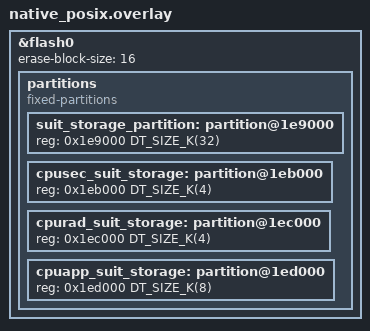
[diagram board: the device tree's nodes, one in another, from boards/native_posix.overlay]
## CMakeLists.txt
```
#
# Copyright (c) 2024 Nordic Semiconductor ASA
#
# SPDX-License-Identifier: LicenseRef-Nordic-5-Clause
#

cmake_minimum_required(VERSION 3.20.0)

find_package(Zephyr REQUIRED HINTS $ENV{ZEPHYR_BASE})

project(integration_suit_component_compatibility_check)
include(../cmake/test_template.cmake)

target_include_directories(app PRIVATE
  ${SUIT_SUBSYS_DIR}/mci/include
  ${SUIT_SUBSYS_DIR}/storage/include
)

target_sources(app PRIVATE
  # Use nRF54H20-specific MCI implementation.
  ${SUIT_SUBSYS_DIR}/mci/src/suit_mci_nrf54h20.c
  ${SUIT_SUBSYS_DIR}/platform/sdfw/src/suit_plat_component_compatibility.c
  ${SUIT_SUBSYS_DIR}/storage/src/suit_storage_nrf54h20.c
)

# Link with the CMake target, that includes SUIT platform internal APIs header
zephyr_library_link_libraries(suit_utils)
zephyr_library_link_libraries(suit_storage_interface)
zephyr_library_link_libraries(suit_platform_interface)
```

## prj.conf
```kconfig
#
# Copyright (c) 2024 Nordic Semiconductor ASA
#
# SPDX-License-Identifier: LicenseRef-Nordic-5-Clause
#

CONFIG_ZTEST=y

CONFIG_SUIT=y
CONFIG_SUIT_PROCESSOR=y
CONFIG_SUIT_UTILS=y
CONFIG_SUIT_MEMPTR_STORAGE=y

# Enable component-compatibility checks
CONFIG_SUIT_PLATFORM=y
CONFIG_SUIT_PLATFORM_VARIANT_SDFW=y

CONFIG_SUIT_STORAGE=y
CONFIG_SUIT_METADATA=y
# nRF54H20 storage uses SHA-256 to protect MPI and NVVs:
CONFIG_SUIT_CRYPTO=y
CONFIG_SUIT_EXECUTION_MODE=y

CONFIG_ZCBOR=y
CONFIG_ZCBOR_CANONICAL=y

CONFIG_FLASH=y

# Mock SDFW arbiter
CONFIG_MOCK_SDFW_ARBITER=y
```

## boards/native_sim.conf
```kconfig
#
# Copyright (c) 2024 Nordic Semiconductor ASA
#
# SPDX-License-Identifier: LicenseRef-Nordic-5-Clause
#

CONFIG_FLASH_SIMULATOR=y
# Mock processor IDs, defined in nrfx
CONFIG_MOCK_NRFX=y
```

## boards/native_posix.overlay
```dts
/*
 * Copyright (c) 2024 Nordic Semiconductor ASA
 *
 * SPDX-License-Identifier: LicenseRef-Nordic-5-Clause
 */

&flash0 {
	/* Align erase block size with the nRF54H20 MRAM definition. */
	erase-block-size = <16>;

	partitions {
		compatible = "fixed-partitions";
		#address-cells = <1>;
		#size-cells = <1>;

		/* Use the last 32 kB of SecDom SUIT NVM storage. */
		suit_storage_partition: partition@1e9000 {
			reg = <0x1e9000 DT_SIZE_K(32)>;
		};

		/* Use the first 4kB as area reserved for Secure domain. */
		cpusec_suit_storage: partition@1eb000 {
			reg = <0x1eb000 DT_SIZE_K(4)>;
		};

		/* Use the next 4kB as area reserved for Radio domain. */
		cpurad_suit_storage: partition@1ec000 {
			reg = <0x1ec000 DT_SIZE_K(4)>;
		};

		/* Use the next 8kB as area reserved for Application domain. */
		cpuapp_suit_storage: partition@1ed000 {
			reg = <0x1ed000 DT_SIZE_K(8)>;
		};
	};
};
```

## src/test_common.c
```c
/*
 * Copyright (c) 2024 Nordic Semiconductor ASA
 *
 * SPDX-License-Identifier: LicenseRef-Nordic-5-Clause
 */

#include <zephyr/ztest.h>
#include <suit_storage_mpi.h>
#include <suit_plat_mem_util.h>
#include "test_common.h"

#define SUIT_STORAGE_NORDIC_OFFSET FIXED_PARTITION_OFFSET(cpusec_suit_storage)
#define SUIT_STORAGE_NORDIC_SIZE   FIXED_PARTITION_SIZE(cpusec_suit_storage)
#define SUIT_STORAGE_RAD_OFFSET	   FIXED_PARTITION_OFFSET(cpurad_suit_storage)
#define SUIT_STORAGE_RAD_SIZE	   FIXED_PARTITION_SIZE(cpurad_suit_storage)
#define SUIT_STORAGE_APP_OFFSET	   FIXED_PARTITION_OFFSET(cpuapp_suit_storage)
#define SUIT_STORAGE_APP_SIZE	   FIXED_PARTITION_SIZE(cpuapp_suit_storage)

#define SUIT_STORAGE_APP_MPI_SIZE 0xf0
#define SUIT_STORAGE_RAD_MPI_SIZE 0x90

/* clang-format off */

/* RFC4122 uuid5(uuid.NAMESPACE_DNS, 'nordicsemi.com') */
const suit_manifest_class_id_t nordic_vid = {{
	0x76, 0x17, 0xda, 0xa5, 0x71, 0xfd, 0x5a, 0x85,
	0x8f, 0x94, 0xe2, 0x8d, 0x73, 0x5c, 0xe9, 0xf4
}};

/* RFC4122 uuid5(nordic_vid, 'nRF54H20_nordic_top') */
const suit_manifest_class_id_t nordic_top_cid = {{
	0xf0, 0x3d, 0x38, 0x5e, 0xa7, 0x31, 0x56, 0x05,
	0xb1, 0x5d, 0x03, 0x7f, 0x6d, 0xa6, 0x09, 0x7f
}};

/* RFC4122 uuid5(nordic_vid, 'nRF54H20_sec') */
const suit_manifest_class_id_t nordic_sdfw_cid = {{
	0xd9, 0x6b, 0x40, 0xb7, 0x09, 0x2b, 0x5c, 0xd1,
	0xa5, 0x9f, 0x9a, 0xf8, 0x0c, 0x33, 0x7e, 0xba
}};

/* RFC4122 uuid5(nordic_vid, 'nRF54H20_sys') */
const suit_manifest_class_id_t nordic_scfw_cid = {{
	0xc0, 0x8a, 0x25, 0xd7, 0x35, 0xe6, 0x59, 0x2c,
	0xb7, 0xad, 0x43, 0xac, 0xc8, 0xd1, 0xd1, 0xc8
}};

/* RFC4122 uuid5(nordic_vid, 'test_sample_root') */
const suit_manifest_class_id_t app_root_cid = {{
	0x97, 0x05, 0x48, 0x23, 0x4c, 0x3d, 0x59, 0xa1,
	0x89, 0x86, 0xa5, 0x46, 0x60, 0xa1, 0x4b, 0x0a,
}};

/* RFC4122 uuid5(nordic_vid, 'test_sample_app') */
const suit_manifest_class_id_t app_local_cid = {{
	0x5b, 0x46, 0x9f, 0xd1, 0x90, 0xee, 0x53, 0x9c,
	0xa3, 0x18, 0x68, 0x1b, 0x03, 0x69, 0x5e, 0x36,
}};

/* clang-format on */

void erase_area_nordic(void)
{
	/* Clear the whole nordic area */
	const struct device *fdev = SUIT_PLAT_INTERNAL_NVM_DEV;

	zassert_not_null(fdev, "Unable to find a driver to modify MPI area");

	int err = flash_erase(fdev, SUIT_STORAGE_NORDIC_OFFSET, SUIT_STORAGE_NORDIC_SIZE);

	zassert_equal(0, err, "Unable to erase nordic area before test execution");
}

void erase_area_rad(void)
{
	/* Clear the whole radio area */
	const struct device *fdev = SUIT_PLAT_INTERNAL_NVM_DEV;

	zassert_not_null(fdev, "Unable to find a driver to modify MPI area");

	int err = flash_erase(fdev, SUIT_STORAGE_RAD_OFFSET, SUIT_STORAGE_RAD_SIZE);

	zassert_equal(0, err, "Unable to erase radio core area before test execution");
}

void erase_area_app(void)
{
	/* Clear the whole application area */
	const struct device *fdev = SUIT_PLAT_INTERNAL_NVM_DEV;

	zassert_not_null(fdev, "Unable to find a driver to modify MPI area");

	int err = flash_erase(fdev, SUIT_STORAGE_APP_OFFSET, SUIT_STORAGE_APP_SIZE);

	zassert_equal(0, err, "Unable to erase application area before test execution");
}

void write_area_app(void)
{
	/* clang-format off */
	uint8_t mpi_root[] = {
		/* Application root MPI area */
		0x01, /* version */
		0x01, /* downgrade prevention disabled */
		0x02, /* Independent update allowed */
		0x01, /* signature check disabled */
		/* reserved (12) */
		0xFF, 0xFF, 0xFF, 0xFF,
		0xFF, 0xFF, 0xFF, 0xFF, 0xFF, 0xFF, 0xFF, 0xFF,
		/* RFC4122 uuid5(uuid.NAMESPACE_DNS, 'nordicsemi.com') */
		0x76, 0x17, 0xda, 0xa5, 0x71, 0xfd, 0x5a, 0x85,
		0x8f, 0x94, 0xe2, 0x8d, 0x73, 0x5c, 0xe9, 0xf4,
		/* RFC4122 uuid5(nordic_vid, 'test_sample_root') */
		0x97, 0x05, 0x48, 0x23, 0x4c, 0x3d, 0x59, 0xa1,
		0x89, 0x86, 0xa5, 0x46, 0x60, 0xa1, 0x4b, 0x0a,
		/* Application recovery MPI area (48) */
		0xFF, 0xFF, 0xFF, 0xFF, 0xFF, 0xFF, 0xFF, 0xFF,
		0xFF, 0xFF, 0xFF, 0xFF, 0xFF, 0xFF, 0xFF, 0xFF,
		0xFF, 0xFF, 0xFF, 0xFF, 0xFF, 0xFF, 0xFF, 0xFF,
		0xFF, 0xFF, 0xFF, 0xFF, 0xFF, 0xFF, 0xFF, 0xFF,
		0xFF, 0xFF, 0xFF, 0xFF, 0xFF, 0xFF, 0xFF, 0xFF,
		0xFF, 0xFF, 0xFF, 0xFF, 0xFF, 0xFF, 0xFF, 0xFF,
		/* Application local 1 MPI area */
		0x01, /* version */
		0x01, /* downgrade prevention disabled */
		0x01, /* Independent update denied */
		0x01, /* signature check disabled */
		/* reserved (12) */
		0xFF, 0xFF, 0xFF, 0xFF,
		0xFF, 0xFF, 0xFF, 0xFF, 0xFF, 0xFF, 0xFF, 0xFF,
		/* RFC4122 uuid5(uuid.NAMESPACE_DNS, 'nordicsemi.com') */
		0x76, 0x17, 0xda, 0xa5, 0x71, 0xfd, 0x5a, 0x85,
		0x8f, 0x94, 0xe2, 0x8d, 0x73, 0x5c, 0xe9, 0xf4,
		/* RFC4122 uuid5(nordic_vid, 'test_sample_app') */
		0x5b, 0x46, 0x9f, 0xd1, 0x90, 0xee, 0x53, 0x9c,
		0xa3, 0x18, 0x68, 0x1b, 0x03, 0x69, 0x5e, 0x36,
	};
	uint8_t app_digest[] = {
		0x44, 0xdc, 0x3d, 0xc5, 0xf3, 0xab, 0x75, 0xa5,
		0x22, 0xd6, 0x42, 0xce, 0x92, 0xb8, 0xbe, 0xf4,
		0x60, 0xcd, 0x7c, 0xab, 0xfa, 0x18, 0x8b, 0x91,
		0x69, 0x32, 0x0a, 0x8b, 0x9e, 0x35, 0x28, 0xa9,
	};
	/* clang-format on */

	/* Write the sample application area (just the root MPI) and corresponding digest */
	const struct device *fdev = SUIT_PLAT_INTERNAL_NVM_DEV;

	zassert_not_null(fdev, "Unable to find a driver to modify MPI area");

	int err = flash_write(fdev, SUIT_STORAGE_APP_OFFSET, mpi_root, sizeof(mpi_root));

	zassert_equal(0, err,
		      "Unable to store application root MPI contents before test execution");

	err = flash_write(fdev, SUIT_STORAGE_APP_OFFSET + SUIT_STORAGE_APP_MPI_SIZE, app_digest,
			  sizeof(app_digest));
	zassert_equal(0, err, "Unable to store application MPI digest before test execution");
}

void assert_nordic_classes(void)
{
	suit_manifest_class_info_t class_infos[CONFIG_SUIT_STORAGE_N_ENVELOPES];
	size_t class_infos_len = CONFIG_SUIT_STORAGE_N_ENVELOPES;

	/* ASSERT that it is possible to fetch list of supported manifest classes and roles */
	int err = suit_storage_mpi_class_ids_get(class_infos, &class_infos_len);

	zassert_equal(err, SUIT_PLAT_SUCCESS,
		      "Failed to fetch list of supported manifest classes (%d).", err);
	/* ... and MPI reports at least 3 class IDs */
	zassert_true(class_infos_len >= 3,
		     "Invalid number of supported manifest classes (%d < %d).", class_infos_len, 3);
	/* ... and the Nordic top manifest class is supported */
	zassert_mem_equal(class_infos[0].vendor_id, &nordic_vid, sizeof(nordic_vid));
	zassert_mem_equal(class_infos[0].class_id, &nordic_top_cid, sizeof(nordic_top_cid));
	zassert_equal(class_infos[0].role, SUIT_MANIFEST_SEC_TOP, "Invalid class role returned: %d",
		      class_infos[0].role);
	/* ... and the Nordic secure domain update & recovery manifest class is supported */
	zassert_mem_equal(class_infos[1].vendor_id, &nordic_vid, sizeof(nordic_vid));
	zassert_mem_equal(class_infos[1].class_id, &nordic_sdfw_cid, sizeof(nordic_sdfw_cid));
	zassert_equal(class_infos[1].role, SUIT_MANIFEST_SEC_SDFW,
		      "Invalid class role returned: %d", class_infos[3].role);
	/* ... and the Nordic system controller manifest class is supported */
	zassert_mem_equal(class_infos[2].vendor_id, &nordic_vid, sizeof(nordic_vid));
	zassert_mem_equal(class_infos[2].class_id, &nordic_scfw_cid, sizeof(nordic_scfw_cid));
	zassert_equal(class_infos[2].role, SUIT_MANIFEST_SEC_SYSCTRL,
		      "Invalid class role returned: %d", class_infos[3].role);
}

void assert_sample_app_classes(void)
{
	suit_manifest_class_info_t class_infos[CONFIG_SUIT_STORAGE_N_ENVELOPES];
	size_t class_infos_len = CONFIG_SUIT_STORAGE_N_ENVELOPES;

	/* ASSERT that it is possible to fetch list of supported manifest classes and roles */
	int err = suit_storage_mpi_class_ids_get(class_infos, &class_infos_len);

	zassert_equal(err, SUIT_PLAT_SUCCESS,
		      "Failed to fetch list of supported manifest classes (%d).", err);
	/* ... and MPI reports 5 supported class IDs */
	zassert_equal(class_infos_len, 5,
		      "Invalid number of supported manifest classes (%d != %d).", class_infos_len,
		      5);
	/* ... and the sample application root manifest class is supported */
	zassert_mem_equal(class_infos[3].vendor_id, &nordic_vid, sizeof(nordic_vid));
	zassert_mem_equal(class_infos[3].class_id, &app_root_cid, sizeof(app_root_cid));
	zassert_equal(class_infos[3].role, SUIT_MANIFEST_APP_ROOT,
		      "Invalid class role returned: %d", class_infos[4].role);
	/* ... and the sample application local manifest class is supported */
	zassert_mem_equal(class_infos[4].vendor_id, &nordic_vid, sizeof(nordic_vid));
	zassert_mem_equal(class_infos[4].class_id, &app_local_cid, sizeof(app_local_cid));
	zassert_equal(class_infos[4].role, SUIT_MANIFEST_APP_LOCAL_1,
		      "Invalid class role returned: %d", class_infos[4].role);
}
```

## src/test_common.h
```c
/*
 * Copyright (c) 2024 Nordic Semiconductor ASA
 *
 * SPDX-License-Identifier: LicenseRef-Nordic-5-Clause
 */

#ifndef TEST_COMMON_H__
#define TEST_COMMON_H__

#include <suit_metadata.h>

/** Nordic vendor ID UUID */
extern const suit_manifest_class_id_t nordic_vid;

/** Nordic top class ID UUID */
extern const suit_manifest_class_id_t nordic_top_cid;

/** SDFW class ID UUID */
extern const suit_manifest_class_id_t nordic_sdfw_cid;

/** SCFW class ID UUID */
extern const suit_manifest_class_id_t nordic_scfw_cid;

/** Application root class ID UUID */
extern const suit_manifest_class_id_t app_root_cid;

/** Application local class ID UUID */
extern const suit_manifest_class_id_t app_local_cid;

/** @brief Erase MPI area, assigned for Nordic-controlled manifests.
 */
void erase_area_nordic(void);

/** @brief Erase MPI area, assigned for radio core manifests.
 */
void erase_area_rad(void);

/** @brief Erase MPI area, assigned for application manifests.
 */
void erase_area_app(void);

/** @brief Populate part of application MPI area, with sample local and root MPI.
 */
void write_area_app(void);

/** @brief Assert that all Nordic-controlled MPIs are provisioned.
 */
void assert_nordic_classes(void);

/** @brief Assert that application MPIs are provisioned.
 */
void assert_sample_app_classes(void);

#endif /* TEST_COMMON_H__ */
```

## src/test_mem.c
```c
/*
 * Copyright (c) 2024 Nordic Semiconductor ASA
 *
 * SPDX-License-Identifier: LicenseRef-Nordic-5-Clause
 */

#include <zephyr/ztest.h>
#include <mocks_sdfw.h>
#include <suit_plat_component_compatibility.h>
#include <suit_storage.h>
#include <suit_execution_mode.h>
#include <suit_types.h>
#include <suit_plat_mem_util.h>
#include "test_common.h"

static void *test_suite_setup(void)
{
	/* Assuming the device is provisioned with application MPI with root config and sample radio
	 * MPI entry.
	 */
	erase_area_nordic();
	erase_area_rad();
	erase_area_app();
	write_area_app();

	/* ... and SUIT storage is successfully initialized */
	zassert_equal(SUIT_PLAT_SUCCESS, suit_storage_init(), "Failed to initialize SUIT storage");

	/* ... and MPIs are correctly loaded */
	assert_nordic_classes();
	assert_sample_app_classes();

	return NULL;
}

static void test_before(void *data)
{
	/* Reset mocks */
	mocks_sdfw_reset();

	/* Reset common FFF internal structures */
	FFF_RESET_HISTORY();

	/* Set execution mode to the final boot state */
	zassert_equal(SUIT_PLAT_SUCCESS, suit_execution_mode_set(EXECUTION_MODE_POST_INVOKE),
		      "Failed to update execution mode");
}

ZTEST_SUITE(suit_component_compatibility_check_tests, NULL, test_suite_setup, test_before, NULL,
	    NULL);

ZTEST(suit_component_compatibility_check_tests, test_app_local_positive)
{
	/* Sample component:
	 *  - type: MEM
	 *  - processor: Application (2)
	 *  - address: 0x80000
	 *  - size: 0x1000
	 */
	uint8_t test_mem_app[] = {0x84, 0x44, 0x63, 'M',  'E',	'M',  0x41, 0x02, 0x45,
				  0x1A, 0x00, 0x08, 0x00, 0x00, 0x43, 0x19, 0x10, 0x00};
	struct zcbor_string test_id = {
		.value = test_mem_app,
		.len = sizeof(test_mem_app),
	};

	/* GIVEN  the sample compoenent memory is allowed to be modified */
	arbiter_mem_access_check_fake.return_val = ARBITER_STATUS_OK;

	/* WHEN a sample MEM component, covering application area is validated for application
	 * manifest
	 */
	int err = suit_plat_component_compatibility_check(&app_local_cid, &test_id);

	/* THEN the component ID is successfully verified... */
	zassert_equal(
		SUIT_PLAT_SUCCESS, err,
		"Failed to validate application MEM component for application local manifest");

	/* ... and the arbiter was used to check for memory addresses */
	zassert_equal(arbiter_mem_access_check_fake.call_count, 1,
		      "Incorrect number of arbiter_mem_access_check() calls");
}

ZTEST(suit_component_compatibility_check_tests, test_app_radio_exec)
{
	/* Sample component:
	 *  - type: MEM
	 *  - processor: Radio (3)
	 *  - address: 0x80000
	 *  - size: 0x1000
	 */
	uint8_t test_mem_app[] = {0x84, 0x44, 0x63, 'M',  'E',	'M',  0x41, 0x03, 0x45,
				  0x1A, 0x00, 0x08, 0x00, 0x00, 0x43, 0x19, 0x10, 0x00};
	struct zcbor_string test_id = {
		.value = test_mem_app,
		.len = sizeof(test_mem_app),
	};

	/* GIVEN  the sample compoenent memory is allowed to be modified */
	arbiter_mem_access_check_fake.return_val = ARBITER_STATUS_OK;

	/* WHEN a sample MEM component, covering radio area is validated for application manifest */
	int err = suit_plat_component_compatibility_check(&app_local_cid, &test_id);

	/* THEN the component ID is denied... */
	zassert_equal(SUIT_ERR_UNAUTHORIZED_COMPONENT, err,
		      "Failed to block radio MEM component for application local manifest");

	/* ... and the arbiter was not used to check for memory addresses */
	zassert_equal(arbiter_mem_access_check_fake.call_count, 0,
		      "Incorrect number of arbiter_mem_access_check() calls");
}

ZTEST(suit_component_compatibility_check_tests, test_app_local_blocked)
{
	/* Sample component:
	 *  - type: MEM
	 *  - processor: Application (2)
	 *  - address: 0x80000
	 *  - size: 0x1000
	 */
	uint8_t test_mem_app[] = {0x84, 0x44, 0x63, 'M',  'E',	'M',  0x41, 0x02, 0x45,
				  0x1A, 0x00, 0x08, 0x00, 0x00, 0x43, 0x19, 0x10, 0x00};
	struct zcbor_string test_id = {
		.value = test_mem_app,
		.len = sizeof(test_mem_app),
	};

	/* GIVEN  the sample compoenent memory is not allowed to be modified */
	arbiter_mem_access_check_fake.return_val = -1;

	/* WHEN a sample MEM component, covering radio area is validated for application manifest */
	int err = suit_plat_component_compatibility_check(&app_local_cid, &test_id);

	/* THEN the component ID is denied... */
	zassert_equal(
		SUIT_ERR_UNAUTHORIZED_COMPONENT, err,
		"Failed to block MEM component for application local manifest using arbiter API");

	/* ... and the arbiter was used to check for memory addresses */
	zassert_equal(arbiter_mem_access_check_fake.call_count, 1,
		      "Incorrect number of arbiter_mem_access_check() calls");
}

ZTEST(suit_component_compatibility_check_tests, test_app_local_envelope_address_boot)
{
	/* Sample component:
	 *  - type: MEM
	 *  - processor: Application (2)
	 *  - address: 0x80000
	 *  - size: 0x1000
	 */
	uint8_t test_mem_app[] = {0x84, 0x44, 0x63, 'M',  'E',	'M',  0x41, 0x02, 0x45,
				  0x1A, 0x00, 0x08, 0x00, 0x00, 0x43, 0x19, 0x10, 0x00};
	struct zcbor_string test_id = {
		.value = test_mem_app,
		.len = sizeof(test_mem_app),
	};

	/* Update candidate info (1 region):
	 *  - address: 0x80000 size: 0x10
	 */
	suit_plat_mreg_t regions[] = {{
		.mem = suit_plat_mem_ptr_get(0x80000),
		.size = 0x10,
	}};

	/* GIVEN  the sample compoenent memory is allowed to be modified */
	arbiter_mem_access_check_fake.return_val = ARBITER_STATUS_OK;

	/* ... and it overlaps with the current update candiadate */
	zassert_equal(
		SUIT_PLAT_SUCCESS,
		suit_storage_update_cand_set((suit_plat_mreg_t *)regions, ARRAY_SIZE(regions)),
		"Unable to configure update candidate info");

	/* ... and the orchestrator is currently booting from local manifests */
	zassert_equal(SUIT_PLAT_SUCCESS, suit_execution_mode_set(EXECUTION_MODE_INVOKE),
		      "Failed to update execution mode");

	/* WHEN a sample MEM component, covering update candidate area is validated for application
	 * manifest
	 */
	int err = suit_plat_component_compatibility_check(&app_local_cid, &test_id);

	/* THEN the component ID is successfully verified... */
	zassert_equal(
		SUIT_PLAT_SUCCESS, err,
		"Failed to validate application MEM component for application local manifest");

	/* ... and the arbiter was used to check for memory addresses */
	zassert_equal(arbiter_mem_access_check_fake.call_count, 1,
		      "Incorrect number of arbiter_mem_access_check() calls");
}

ZTEST(suit_component_compatibility_check_tests, test_app_local_envelope_address)
{
	/* Sample component:
	 *  - type: MEM
	 *  - processor: Application (2)
	 *  - address: 0x80000
	 *  - size: 0x1000
	 */
	uint8_t test_mem_app[] = {0x84, 0x44, 0x63, 'M',  'E',	'M',  0x41, 0x02, 0x45,
				  0x1A, 0x00, 0x08, 0x00, 0x00, 0x43, 0x19, 0x10, 0x00};
	struct zcbor_string test_id = {
		.value = test_mem_app,
		.len = sizeof(test_mem_app),
	};

	/* Update candidate info (1 region):
	 *  - address: 0x80000 size: 0x10
	 */
	suit_plat_mreg_t regions[] = {{
		.mem = suit_plat_mem_ptr_get(0x80000),
		.size = 0x10,
	}};

	/* GIVEN  the sample compoenent memory is allowed to be modified */
	arbiter_mem_access_check_fake.return_val = ARBITER_STATUS_OK;

	/* ... and it overlaps with the current update candiadate */
	zassert_equal(
		SUIT_PLAT_SUCCESS,
		suit_storage_update_cand_set((suit_plat_mreg_t *)regions, ARRAY_SIZE(regions)),
		"Unable to configure update candidate info");

	/* ... and the orchestrator is currently processing the candidate */
	zassert_equal(SUIT_PLAT_SUCCESS, suit_execution_mode_set(EXECUTION_MODE_INSTALL),
		      "Failed to update execution mode");

	/* WHEN a sample MEM component, covering update candidate area is validated for application
	 * manifest
	 */
	int err = suit_plat_component_compatibility_check(&app_local_cid, &test_id);

	/* THEN the component ID is denied... */
	zassert_equal(SUIT_ERR_UNAUTHORIZED_COMPONENT, err,
		      "Failed to block MEM component addressing dfu partition during update for "
		      "application local manifest");

	/* ... and the arbiter was not used to check for memory addresses */
	zassert_equal(arbiter_mem_access_check_fake.call_count, 0,
		      "Incorrect number of arbiter_mem_access_check() calls");
}

ZTEST(suit_component_compatibility_check_tests, test_app_local_before_envelope_address)
{
	/* Sample component:
	 *  - type: MEM
	 *  - processor: Application (2)
	 *  - address: 0x80000
	 *  - size: 0x1000
	 */
	uint8_t test_mem_app[] = {0x84, 0x44, 0x63, 'M',  'E',	'M',  0x41, 0x02, 0x45,
				  0x1A, 0x00, 0x08, 0x00, 0x00, 0x43, 0x19, 0x10, 0x00};
	struct zcbor_string test_id = {
		.value = test_mem_app,
		.len = sizeof(test_mem_app),
	};

	/* Update candidate info (1 region):
	 *  - address: 0x7f000 size: 0x1001
	 */
	suit_plat_mreg_t regions[] = {{
		.mem = suit_plat_mem_ptr_get(0x7f000),
		.size = 0x1001,
	}};

	/* GIVEN  the sample compoenent memory is allowed to be modified */
	arbiter_mem_access_check_fake.return_val = ARBITER_STATUS_OK;

	/* ... and it overlaps with the current update candiadate */
	zassert_equal(
		SUIT_PLAT_SUCCESS,
		suit_storage_update_cand_set((suit_plat_mreg_t *)regions, ARRAY_SIZE(regions)),
		"Unable to configure update candidate info");

	/* ... and the orchestrator is currently processing the candidate */
	zassert_equal(SUIT_PLAT_SUCCESS, suit_execution_mode_set(EXECUTION_MODE_INSTALL),
		      "Failed to update execution mode");

	/* WHEN a sample MEM component, covering update candidate area is validated for application
	 * manifest
	 */
	int err = suit_plat_component_compatibility_check(&app_local_cid, &test_id);

	/* THEN the component ID is denied... */
	zassert_equal(SUIT_ERR_UNAUTHORIZED_COMPONENT, err,
		      "Failed to block MEM component addressing dfu partition during update for "
		      "application local manifest");

	/* ... and the arbiter was not used to check for memory addresses */
	zassert_equal(arbiter_mem_access_check_fake.call_count, 0,
		      "Incorrect number of arbiter_mem_access_check() calls");
}

ZTEST(suit_component_compatibility_check_tests, test_app_local_after_envelope_address)
{
	/* Sample component:
	 *  - type: MEM
	 *  - processor: Application (2)
	 *  - address: 0x80000
	 *  - size: 0x1000
	 */
	uint8_t test_mem_app[] = {0x84, 0x44, 0x63, 'M',  'E',	'M',  0x41, 0x02, 0x45,
				  0x1A, 0x00, 0x08, 0x00, 0x00, 0x43, 0x19, 0x10, 0x00};
	struct zcbor_string test_id = {
		.value = test_mem_app,
		.len = sizeof(test_mem_app),
	};

	/* Update candidate info (1 region):
	 *  - address: 0x80fff size: 0x10
	 */
	suit_plat_mreg_t regions[] = {{
		.mem = suit_plat_mem_ptr_get(0x80fff),
		.size = 0x10,
	}};

	/* GIVEN  the sample compoenent memory is allowed to be modified */
	arbiter_mem_access_check_fake.return_val = ARBITER_STATUS_OK;

	/* ... and it overlaps with the current update candiadate */
	zassert_equal(
		SUIT_PLAT_SUCCESS,
		suit_storage_update_cand_set((suit_plat_mreg_t *)regions, ARRAY_SIZE(regions)),
		"Unable to configure update candidate info");

	/* ... and the orchestrator is currently processing the candidate */
	zassert_equal(SUIT_PLAT_SUCCESS, suit_execution_mode_set(EXECUTION_MODE_INSTALL),
		      "Failed to update execution mode");

	/* WHEN a sample MEM component, covering update candidate area is validated for application
	 * manifest
	 */
	int err = suit_plat_component_compatibility_check(&app_local_cid, &test_id);

	/* THEN the component ID is denied... */
	zassert_equal(SUIT_ERR_UNAUTHORIZED_COMPONENT, err,
		      "Failed to block MEM component addressing dfu partition during update for "
		      "application local manifest");

	/* ... and the arbiter was not used to check for memory addresses */
	zassert_equal(arbiter_mem_access_check_fake.call_count, 0,
		      "Incorrect number of arbiter_mem_access_check() calls");
}

ZTEST(suit_component_compatibility_check_tests, test_app_local_inside_envelope)
{
	/* Sample component:
	 *  - type: MEM
	 *  - processor: Application (2)
	 *  - address: 0x80000
	 *  - size: 0x1000
	 */
	uint8_t test_mem_app[] = {0x84, 0x44, 0x63, 'M',  'E',	'M',  0x41, 0x02, 0x45,
				  0x1A, 0x00, 0x08, 0x00, 0x00, 0x43, 0x19, 0x10, 0x00};
	struct zcbor_string test_id = {
		.value = test_mem_app,
		.len = sizeof(test_mem_app),
	};

	/* Update candidate info (1 region):
	 *  - address: 0x7f000 size: 0x3000
	 */
	suit_plat_mreg_t regions[] = {{
		.mem = suit_plat_mem_ptr_get(0x7f000),
		.size = 0x3000,
	}};

	/* GIVEN  the sample compoenent memory is allowed to be modified */
	arbiter_mem_access_check_fake.return_val = ARBITER_STATUS_OK;

	/* ... and it overlaps with the current update candiadate */
	zassert_equal(
		SUIT_PLAT_SUCCESS,
		suit_storage_update_cand_set((suit_plat_mreg_t *)regions, ARRAY_SIZE(regions)),
		"Unable to configure update candidate info");

	/* ... and the orchestrator is currently processing the candidate */
	zassert_equal(SUIT_PLAT_SUCCESS, suit_execution_mode_set(EXECUTION_MODE_INSTALL),
		      "Failed to update execution mode");

	/* WHEN a sample MEM component, covering update candidate area is validated for application
	 * manifest
	 */
	int err = suit_plat_component_compatibility_check(&app_local_cid, &test_id);

	/* THEN the component ID is denied... */
	zassert_equal(SUIT_ERR_UNAUTHORIZED_COMPONENT, err,
		      "Failed to block MEM component addressing dfu partition during update for "
		      "application local manifest");

	/* ... and the arbiter was not used to check for memory addresses */
	zassert_equal(arbiter_mem_access_check_fake.call_count, 0,
		      "Incorrect number of arbiter_mem_access_check() calls");
}

ZTEST(suit_component_compatibility_check_tests, test_app_local_include_envelope)
{
	/* Sample component:
	 *  - type: MEM
	 *  - processor: Application (2)
	 *  - address: 0x80000
	 *  - size: 0x1000
	 */
	uint8_t test_mem_app[] = {0x84, 0x44, 0x63, 'M',  'E',	'M',  0x41, 0x02, 0x45,
				  0x1A, 0x00, 0x08, 0x00, 0x00, 0x43, 0x19, 0x10, 0x00};
	struct zcbor_string test_id = {
		.value = test_mem_app,
		.len = sizeof(test_mem_app),
	};

	/* Update candidate info (1 region):
	 *  - address: 0x80f00 size: 0x10
	 */
	suit_plat_mreg_t regions[] = {{
		.mem = suit_plat_mem_ptr_get(0x80f00),
		.size = 0x10,
	}};

	/* GIVEN  the sample compoenent memory is allowed to be modified */
	arbiter_mem_access_check_fake.return_val = ARBITER_STATUS_OK;

	/* ... and it overlaps with the current update candiadate */
	zassert_equal(
		SUIT_PLAT_SUCCESS,
		suit_storage_update_cand_set((suit_plat_mreg_t *)regions, ARRAY_SIZE(regions)),
		"Unable to configure update candidate info");

	/* ... and the orchestrator is currently processing the candidate */
	zassert_equal(SUIT_PLAT_SUCCESS, suit_execution_mode_set(EXECUTION_MODE_INSTALL),
		      "Failed to update execution mode");

	/* WHEN a sample MEM component, covering update candidate area is validated for application
	 * manifest
	 */
	int err = suit_plat_component_compatibility_check(&app_local_cid, &test_id);

	/* THEN the component ID is denied... */
	zassert_equal(SUIT_ERR_UNAUTHORIZED_COMPONENT, err,
		      "Failed to block MEM component addressing dfu partition during update for "
		      "application local manifest");

	/* ... and the arbiter was not used to check for memory addresses */
	zassert_equal(arbiter_mem_access_check_fake.call_count, 0,
		      "Incorrect number of arbiter_mem_access_check() calls");
}

ZTEST(suit_component_compatibility_check_tests, test_app_local_surrounded)
{
	/* Sample component:
	 *  - type: MEM
	 *  - processor: Application (2)
	 *  - address: 0x80000
	 *  - size: 0x1000
	 */
	uint8_t test_mem_app[] = {0x84, 0x44, 0x63, 'M',  'E',	'M',  0x41, 0x02, 0x45,
				  0x1A, 0x00, 0x08, 0x00, 0x00, 0x43, 0x19, 0x10, 0x00};
	struct zcbor_string test_id = {
		.value = test_mem_app,
		.len = sizeof(test_mem_app),
	};

	/* Update candidate info (2 regions):
	 *  - address: 0x7f000 size: 0x1000
	 *  - address: 0x82000 size: 0x1000
	 */
	/* clang-format off */
	suit_plat_mreg_t regions[] = {
		{
			.mem = suit_plat_mem_ptr_get(0x7f000),
			.size = 0x1000,
		},
		{
			.mem = suit_plat_mem_ptr_get(0x82000),
			.size = 0x1000,
		}
	};
	/* clang-format on */

	/* GIVEN  the sample compoenent memory is allowed to be modified */
	arbiter_mem_access_check_fake.return_val = ARBITER_STATUS_OK;

	/* ... and it overlaps with the current update candiadate */
	zassert_equal(
		SUIT_PLAT_SUCCESS,
		suit_storage_update_cand_set((suit_plat_mreg_t *)regions, ARRAY_SIZE(regions)),
		"Unable to configure update candidate info");

	/* ... and the orchestrator is currently processing the candidate */
	zassert_equal(SUIT_PLAT_SUCCESS, suit_execution_mode_set(EXECUTION_MODE_INSTALL),
		      "Failed to update execution mode");

	/* WHEN a sample MEM component, covering area between update candidate regions is validated
	 * for application manifest
	 */
	int err = suit_plat_component_compatibility_check(&app_local_cid, &test_id);

	/* THEN the component ID is successfully verified... */
	zassert_equal(
		SUIT_PLAT_SUCCESS, err,
		"Failed to validate application MEM component for application local manifest");

	/* ... and the arbiter was used to check for memory addresses */
	zassert_equal(arbiter_mem_access_check_fake.call_count, 1,
		      "Incorrect number of arbiter_mem_access_check() calls");
}

ZTEST(suit_component_compatibility_check_tests, test_app_root_invalid_exec_type)
{
	/* Sample component:
	 *  - type: MEM
	 *  - processor: Application (2)
	 *  - address: 0x80000
	 *  - size: 0x1000
	 */
	uint8_t test_mem_app[] = {0x84, 0x44, 0x63, 'M',  'E',	'M',  0x41, 0x02, 0x45,
				  0x1A, 0x00, 0x08, 0x00, 0x00, 0x43, 0x19, 0x10, 0x00};
	struct zcbor_string test_id = {
		.value = test_mem_app,
		.len = sizeof(test_mem_app),
	};

	/* GIVEN  the sample compoenent memory is allowed to be modified */
	arbiter_mem_access_check_fake.return_val = ARBITER_STATUS_OK;

	/* WHEN a sample MEM component, covering radio area is validated for application manifest */
	int err = suit_plat_component_compatibility_check(&app_root_cid, &test_id);

	/* THEN the component ID is denied... */
	zassert_equal(SUIT_ERR_UNAUTHORIZED_COMPONENT, err,
		      "Failed to block executable MEM component in root manifest");

	/* ... and the arbiter was not used to check for memory addresses */
	zassert_equal(arbiter_mem_access_check_fake.call_count, 0,
		      "Incorrect number of arbiter_mem_access_check() calls");
}

ZTEST(suit_component_compatibility_check_tests, test_app_root_invalid_nonexec_type)
{
	/* Sample component:
	 *  - type: MEM
	 *  - processor: non-executable (-1)
	 *  - address: 0x80000
	 *  - size: 0x1000
	 */
	uint8_t test_mem_app[] = {0x84, 0x44, 0x63, 'M',  'E',	'M',  0x41, 0x20, 0x45,
				  0x1A, 0x00, 0x08, 0x00, 0x00, 0x43, 0x19, 0x10, 0x00};
	struct zcbor_string test_id = {
		.value = test_mem_app,
		.len = sizeof(test_mem_app),
	};

	/* GIVEN  the sample compoenent memory is allowed to be modified */
	arbiter_mem_access_check_fake.return_val = ARBITER_STATUS_OK;

	/* WHEN a sample MEM component, covering radio area is validated for application manifest */
	int err = suit_plat_component_compatibility_check(&app_root_cid, &test_id);

	/* THEN the component ID is denied... */
	zassert_equal(SUIT_ERR_UNAUTHORIZED_COMPONENT, err,
		      "Failed to block non-executable MEM component in root manifest");

	/* ... and the arbiter was not used to check for memory addresses */
	zassert_equal(arbiter_mem_access_check_fake.call_count, 0,
		      "Incorrect number of arbiter_mem_access_check() calls");
}
```
